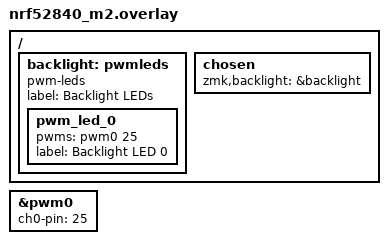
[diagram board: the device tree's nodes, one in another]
#include <dt-bindings/led/led.h>

&pwm0 {
    status = "okay";
    ch0-pin = <25>;
    /* ch0-inverted; */
};

/ {
    backlight: pwmleds {
        compatible = "pwm-leds";
        label = "Backlight LEDs";
        pwm_led_0 {
            pwms = <&pwm0 25>;
            label = "Backlight LED 0";
        };
    };
};

/ {
    chosen {
        zmk,backlight = &backlight;
    };
};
